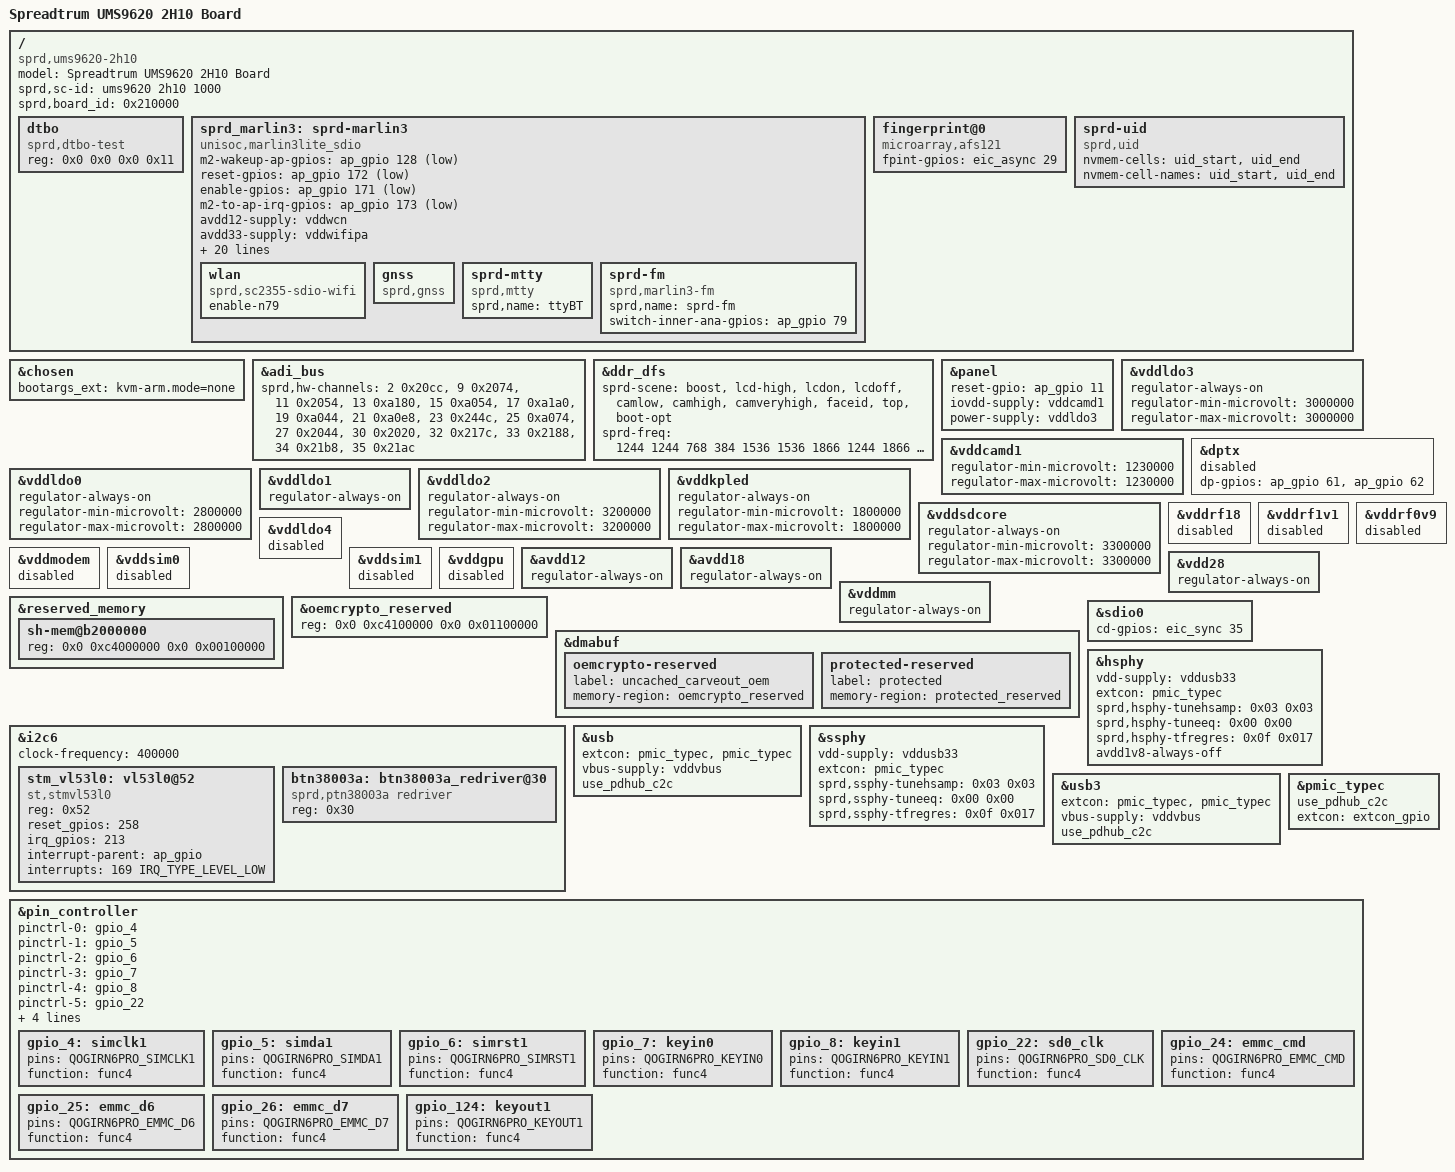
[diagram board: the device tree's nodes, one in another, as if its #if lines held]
// SPDX-License-Identifier: (Licenseref-Unisoc-General-1.0 OR GPL-2.0-only)
/*
 * ums9620-2h10-overlay.dts - Unisoc platform device
 *
 * Copyright 2022 Unisoc(Shanghai) Technologies Co.Ltd
 *
 * Licensed under the Unisoc General Software License, version 1.0 (the
 * License);
 * you may not use this file except in compliance with the License.
 * You may obtain a copy of the License at
 * https://www.unisoc.com/en_us/license/UNISOC_GENERAL_LICENSE_V1.0-EN_US
 * Software distributed under the License is distributed on an "AS IS" BASIS,
 * WITHOUT WARRANTIES OF ANY KIND, either express or implied.
 * See the Unisoc General Software License, version 1.0 for more details.
 *
 * Alternatively you can use and distribute this file under the terms of the
 * GNU General Public License version 2, provided that it has to be used
 *  (including but not limited to combining, linking) with any other file under
 * the GNU General Public License version 2 on platforms that use Unisoc Chips.
 */
/*#include <dt-bindings/wdv/wdv.h>*/

/dts-v1/;
/plugin/;
#include <dt-bindings/gpio/gpio.h>
#include <dt-bindings/interrupt-controller/arm-gic.h>
#include <dt-bindings/clock/sprd,ums9620-clk.h>
#include <dt-bindings/usb/pd.h>
#include "../../lcd/6p77_ramless/zte_lcd_boe_rm69220_boe_6p77_ramless_fhd.dtsi"
#include "../../lcd/zte_lcd_dummy_mipi_cabc.dtsi"
#include "zte_lcd.dtsi"
#include "zte_nfc_thn31.dtsi"
#include "../../reserved-memory/ums9620-2h10-overlay.dtsi"
/* #include "../../sound/ums9620-overlay.dtsi" */  /*zte del for not use hdmi*/
#include <dt-bindings/mfd/sprd,ump9620-regs.h>
#include <dt-bindings/mfd/sprd,ump9620-mask.h>
#include <dt-bindings/input/input.h>
#include <dt-bindings/clock/sprd,ums9620-clk.h>
#include "../../wcn/wcn_modules.h"
#include "../../wcn/interface/wcn-sdio-register.dtsi"
#include "../../wcn/chip/wcn-marlin3lite-umw2652-register.dtsi"

/ {

	model = "Spreadtrum UMS9620 2H10 Board";

	compatible = "sprd,ums9620-2h10", "sprd,ums9620";

	sprd,sc-id = "ums9620 2h10 1000";

	sprd,board_id = <0x210000>; //XXYY00:base board,XXYY00~XXYYFF:customize board

	fragment {
		target-path = "/";
		__overlay__ {
			#address-cells = <2>;
			#size-cells = <2>;

			dtbo: dtbo {
				compatible = "sprd,dtbo-test";
				reg = <0x0 0x0 0x0 0x11>;
			};
			sprd_marlin3: sprd-marlin3 {
				compatible = "unisoc,marlin3lite_sdio";
				m2-wakeup-ap-gpios = <&ap_gpio 128 GPIO_ACTIVE_LOW>;
				reset-gpios = <&ap_gpio 172 GPIO_ACTIVE_LOW>;
				enable-gpios = <&ap_gpio 171 GPIO_ACTIVE_LOW>;
				m2-to-ap-irq-gpios = <&ap_gpio 173 GPIO_ACTIVE_LOW>;
				/* xtal-26m-clk-type = "TCXO"; */
				avdd12-supply = <&vddwcn>;
				avdd33-supply = <&vddwifipa>;
				dcxo18-supply = <&vddsim2>;
				clock-names = "clk_32k","source","enable";
				clocks = <&aonapb_gate CLK_AUX0>,
					 <&ext_32k>,
					 <&aonapb_gate CLK_AUX0_EB>;
				extcon = <&sdio1>;
				sdhci-name = <&sdio1>;
				sprd,check-emmc-ufs = "need_to_check_emmc_or_ufs";
				sprd,btwf-file-name = "/dev/block/by-name/wcnmodem";
				sprd,gnss-file-name = "/vendor/firmware/gnssmodem.bin";
				btwf-wakeup-lock;
				adma-tx;
				adma-rx;
				n79-mode-support;
				/*
				 * bound parameter:
				 * [0]:addr offset, [1]:mask, [2]:unboundval, [3]:boundval
				 */
				avdd12-parent-bound-chip = <REG_ANA_SLP_DCDC_PD_CTRL MASK_ANA_SLP_DCDCGEN1_PD_EN 0x0 MASK_ANA_SLP_DCDCGEN1_PD_EN>;
				avdd12-bound-wbreq = <REG_ANA_LDO_XTL_EN10 MASK_ANA_LDO_VDDWCN_EXT_XTL3_EN 0x0 MASK_ANA_LDO_VDDWCN_EXT_XTL3_EN>;
				avdd33-bound-wbreq = <REG_ANA_LDO_XTL_EN11 MASK_ANA_LDO_VDDWIFIPA_EXT_XTL3_EN 0x0 MASK_ANA_LDO_VDDWIFIPA_EXT_XTL3_EN>;

				wlan {
					compatible = "sprd,sc2355-sdio-wifi";
					enable-n79;
				};

				gnss {
					compatible = "sprd,gnss";
				};

				sprd-mtty {
					compatible = "sprd,mtty";
					sprd,name = "ttyBT";
				};

				sprd-fm {
					compatible = "sprd,marlin3-fm";
					sprd,name = "sprd-fm";
					switch-inner-ana-gpios = <&ap_gpio 79 0>; /*support lna switch */
				};
			};

			fingerprint@0 {
				compatible = "microarray,afs121";
				fpint-gpios = <&eic_async 29 0>;
  			};

			sprd-uid {
				compatible = "sprd,uid";
				nvmem-cells = <&uid_start>, <&uid_end>;
				nvmem-cell-names = "uid_start", "uid_end";
			};

		};
	};
};

&chosen {
	bootargs_ext = "kvm-arm.mode=none";
};

&adi_bus {
	sprd,hw-channels = <2 0x20cc>, <9 0x2074>, <11 0x2054>, <13 0xa180>,
			<15 0xa054>, <17 0xa1a0>, <19 0xa044>, <21 0xa0e8>,
			<23 0x244c>, <25 0xa074>, <27 0x2044>, <30 0x2020>,
			<32 0x217c>, <33 0x2188>, <34 0x21b8>, <35 0x21ac>;
};

&ddr_dfs {
		sprd-scene = "boost", "lcd-high", "lcdon", "lcdoff", "camlow",
			"camhigh", "camveryhigh", "faceid", "top", "boot-opt";
		sprd-freq = <1244 1244 768 384 1536 1536 1866 1244 1866 1866>;
};

&panel {
	/*iovdd-gpio = <&ap_gpio 189 GPIO_ACTIVE_HIGH>;*/
	reset-gpio = <&ap_gpio 11 GPIO_ACTIVE_HIGH>;
	iovdd-supply = <&vddcamd1>;
	power-supply = <&vddldo3>;
};

/* enable lcd vddcammot1 */
&vddldo3 {
	regulator-always-on;
	regulator-min-microvolt = <3000000>;
	regulator-max-microvolt = <3000000>;
};

&vddcamd1 {
	regulator-min-microvolt = <1230000>;
	regulator-max-microvolt = <1230000>;
};
&dptx {
	status = "disabled";
	dp-gpios = <&ap_gpio 61 GPIO_ACTIVE_HIGH>,
			<&ap_gpio 62 GPIO_ACTIVE_HIGH>;
};


/* enable vddldo0 for sub skey */
&vddldo0 {
	regulator-always-on;
	regulator-min-microvolt = <2800000>;
	regulator-max-microvolt = <2800000>;
};

&vddldo1 {
	regulator-always-on;
};

/* enable sensor vddldo2 for als/prx */
&vddldo2 {
	regulator-always-on;
	regulator-min-microvolt = <3200000>;
	regulator-max-microvolt = <3200000>;
};

/* enable als sensor vdd_als vddkpled */
&vddkpled {
	regulator-always-on;
	regulator-min-microvolt = <1800000>;
	regulator-max-microvolt = <1800000>;
};

/* enable prox sensor vled vddsdcore */
&vddsdcore {
	regulator-always-on;
	regulator-min-microvolt = <3300000>;
	regulator-max-microvolt = <3300000>;
};

&vddrf18 {
	status = "disabled";
};

&vddrf1v1 {
	status = "disabled";
};

&vddrf0v9 {
	status = "disabled";
};

&vddldo4 {
	status = "disabled";
};

&vddmodem {
	status = "disabled";
};

&vddsim0 {
	status = "disabled";
};

&vddsim1 {
	status = "disabled";
};

&vddgpu {
	status = "disabled";
};

&avdd12 {
	regulator-always-on;
};

&avdd18 {
	regulator-always-on;
};

&vdd28 {
	regulator-always-on;
};

&vddmm {
	regulator-always-on;
};

&reserved_memory {
	/* the @addr value is not accurate on N6Pro, please refer to the reg value */
	sh-mem@b2000000{
		reg = <0x0 0xc4000000 0x0 0x00100000>;
	};
};

&oemcrypto_reserved{
	reg = <0x0 0xc4100000 0x0 0x01100000>;
};

&dmabuf {
#ifdef BSP_KERNEL_CONFIG_WIDEVINE_L1
	oemcrypto-reserved {
		label = "uncached_carveout_oem";
		memory-region = <&oemcrypto_reserved>;
	};
#endif

	protected-reserved {
		label = "protected";
		memory-region = <&protected_reserved>;
	};
};

&sdio0 {
	cd-gpios = <&eic_sync 35 GPIO_ACTIVE_HIGH>;
};



&i2c6 {
	status = "okay";
	clock-frequency = <400000>;


	stm_vl53l0: vl53l0@52 {
		compatible = "st,stmvl53l0";
		reg = <0x52>;
		reset_gpios = <258>;
		irq_gpios = <213>;
		interrupt-parent = <&ap_gpio>;
		interrupts = <169 IRQ_TYPE_LEVEL_LOW>;
	};

	btn38003a: btn38003a_redriver@30 {
		compatible = "sprd,ptn38003a redriver";
		reg = <0x30>;
	};

};

&hsphy {
	vdd-supply = <&vddusb33>;
	extcon = <&pmic_typec>;
	/* first value is reserverd, the second is host */
	sprd,hsphy-tunehsamp = /bits/ 8 <0x03 0x03>;
	sprd,hsphy-tuneeq = /bits/ 8 <0x00 0x00>;
	sprd,hsphy-tfregres = /bits/ 8 <0x0f 0x017>;
	/* avdd1v8 always off */
	avdd1v8-always-off;
	status = "okay";
};

&usb {
	extcon = <&pmic_typec>, <&pmic_typec>;
	vbus-supply = <&vddvbus>;
	status = "okay";
	use_pdhub_c2c;
};

&ssphy {
	vdd-supply = <&vddusb33>;
	extcon = <&pmic_typec>;
	/* first value is device eye-patt setting, the second is host */
	sprd,ssphy-tunehsamp = /bits/ 8 <0x03 0x03>;
	sprd,ssphy-tuneeq = /bits/ 8 <0x00 0x00>;
	sprd,ssphy-tfregres = /bits/ 8 <0x0f 0x017>;
	status = "okay";
};

&usb3 {
	extcon = <&pmic_typec>, <&pmic_typec>;
	vbus-supply = <&vddvbus>;
	status = "okay";
	use_pdhub_c2c;
};

&pmic_typec {
	use_pdhub_c2c;
	extcon = <&extcon_gpio>;
	status = "okay";
};

&pin_controller {
	pinctrl-names =
	/* IM1_CLK ,SIM1_DA ,SIM1_RST ,keyin0 */
	 "gpio_4", "gpio_5", "gpio_6", "gpio_7",
	/* keyin1 ,sd0_clk, emmc_cmd */
	"gpio_8", "gpio_22", "gpio_24",
	/* emmc_d6, emmc_d7, emmc_d7 */
	"gpio_25", "gpio_26", "gpio_124";

	pinctrl-0 = <&gpio_4>;
	pinctrl-1 = <&gpio_5>;
	pinctrl-2 = <&gpio_6>;
	pinctrl-3 = <&gpio_7>;
	pinctrl-4 = <&gpio_8>;
	pinctrl-5 = <&gpio_22>;
	pinctrl-6 = <&gpio_24>;
	pinctrl-7 = <&gpio_25>;
	pinctrl-8 = <&gpio_26>;
	pinctrl-9 = <&gpio_124>;

	gpio_4: simclk1 {
		pins = "QOGIRN6PRO_SIMCLK1";
		function = "func4";
	};

	gpio_5: simda1 {
		pins = "QOGIRN6PRO_SIMDA1";
		function = "func4";
	};

	gpio_6: simrst1 {
		pins = "QOGIRN6PRO_SIMRST1";
		function = "func4";
	};

	gpio_7: keyin0 {
		pins = "QOGIRN6PRO_KEYIN0";
		function = "func4";
	};

	gpio_8: keyin1 {
		pins = "QOGIRN6PRO_KEYIN1";
		function = "func4";
	};

	gpio_22: sd0_clk {
		pins = "QOGIRN6PRO_SD0_CLK";
		function = "func4";
	};

	gpio_24: emmc_cmd {
		pins = "QOGIRN6PRO_EMMC_CMD";
		function = "func4";
	};

	gpio_25: emmc_d6 {
		pins = "QOGIRN6PRO_EMMC_D6";
		function = "func4";
	};

	gpio_26: emmc_d7 {
		pins = "QOGIRN6PRO_EMMC_D7";
		function = "func4";
	};

	gpio_124: keyout1 {
		pins = "QOGIRN6PRO_KEYOUT1";
		function = "func4";
	};
};

